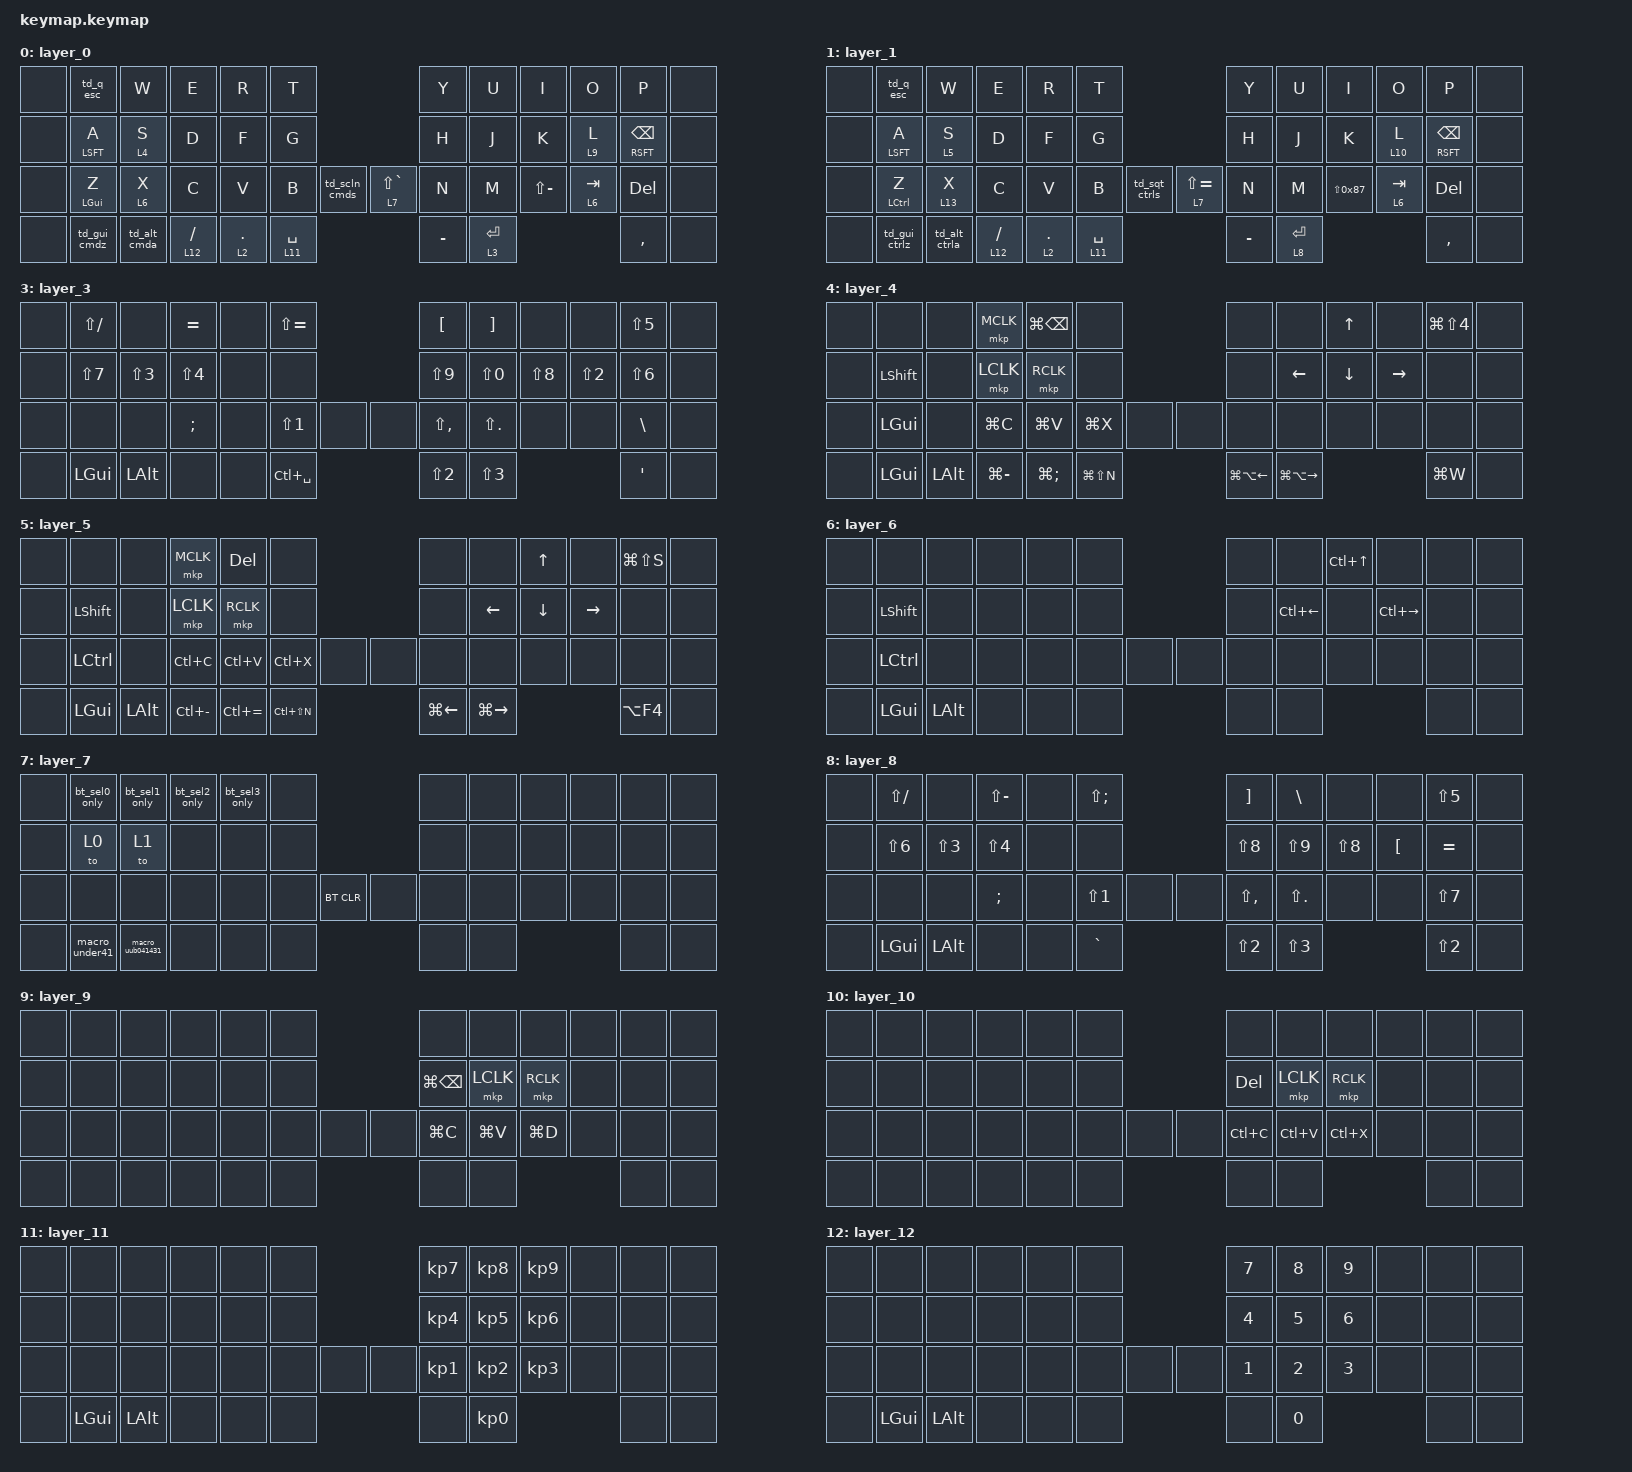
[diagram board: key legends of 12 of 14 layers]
sd#include <dt-bindings/zmk/mouse.h>
#include <behaviors.dtsi>
#include <dt-bindings/zmk/keys.h>
#include <dt-bindings/zmk/bt.h>

/ {


    behaviors {
          macro_under41: macro_under41 {
              compatible = "zmk,behavior-macro";
              #binding-cells = <0>;
              bindings =
              <&kp U>,
              <&kp N>,
              <&kp D>,
              <&kp E>,
        	  <&kp R>,
              <&kp N4>,
              <&kp N1>;
           };
        macro_uub041431: macro_uub041431 {
            compatible = "zmk,behavior-macro";
            #binding-cells = <0>;
            bindings =
            <&kp U>,
            <&kp U>,
            <&kp B>,
            <&kp N0>,
            <&kp N4>,
            <&kp N1>,
            <&kp N4>,
            <&kp N3>,
            <&kp N1>;
          };

         
        bt_sel0_only: bt_sel0_only {
            compatible = "zmk,behavior-macro";
            #binding-cells = <0>;
            bindings =
                <&bt BT_SEL 0>,
                <&bt BT_DISC 1>,
                <&bt BT_DISC 2>,
                <&bt BT_DISC 3>;
        };
       bt_sel1_only: bt_sel1_only {
            compatible = "zmk,behavior-macro";
            #binding-cells = <0>;
            bindings =
                <&bt BT_SEL 1>,
                <&bt BT_DISC 0>,
                <&bt BT_DISC 2>,
                <&bt BT_DISC 3>;
        };
       bt_sel2_only: bt_sel2_only {
            compatible = "zmk,behavior-macro";
            #binding-cells = <0>;
            bindings =
                <&bt BT_SEL 2>,
                <&bt BT_DISC 0>,
                <&bt BT_DISC 1>,
                <&bt BT_DISC 3>;
        };
        bt_sel3_only: bt_sel3_only {
            compatible = "zmk,behavior-macro";
            #binding-cells = <0>;
            bindings =
                <&bt BT_SEL 3>,
                <&bt BT_DISC 1>,
                <&bt BT_DISC 2>,
                <&bt BT_DISC 0>;
        };



   
         mt_cmd_z: mt_cmd_z {                 //Z to komanndo no taiminngutyousei
             compatible = "zmk,behavior-hold-tap";
             #binding-cells = <2>;
             flavor = "tap-preferred";
             tapping-term-ms = <320>;
             bindings = <&kp>, <&kp>;
          };

         mt_ctrl_z: mt_ctrl_z {              //Z to konntoro-ru no taiminngutyousei
             compatible = "zmk,behavior-hold-tap";
             #binding-cells = <2>;
             flavor = "tap-preferred";
             tapping-term-ms = <320>;
             bindings = <&kp>, <&kp>;
          };


    
          mt_lsft_a: mt_lsft_a {              //A to sihuto no taiminngutyousei
               compatible = "zmk,behavior-hold-tap";
               #binding-cells = <2>;
               flavor = "tap-preferred";
               tapping-term-ms = <320>;
               bindings = <&kp>, <&kp>;
           };

         mt_rsft_bspc: mt_rsft_bspc {            //bakkusupe-su to migi sihuto no taiminngutyousei
              compatible = "zmk,behavior-hold-tap";
              #binding-cells = <2>;
              flavor = "tap-preferred";
              tapping-term-ms = <320>;
              bindings = <&kp>, <&kp>;
         };
        td_q_esc: td_q_esc {
            compatible = "zmk,behavior-tap-dance";
            #binding-cells = <0>;
            tapping-term-ms = <200>;
            bindings = < &kp Q &kp ESC >;
        };


        td_gui_cmdz: td_gui_cmdz {   //
            compatible = "zmk,behavior-tap-dance";
            #binding-cells = <0>;
            tapping-term-ms = <200>;
            bindings = < &kp LGUI &kp LG(Z) >;
        };
        td_gui_ctrlz: td_gui_ctrlz {    //
            compatible = "zmk,behavior-tap-dance";
            #binding-cells = <0>;
            tapping-term-ms = <200>;
            bindings = < &kp LGUI &kp LC(Z) >;
        };
        td_alt_cmda: td_alt_cmda {    //
            compatible = "zmk,behavior-tap-dance";
            #binding-cells = <0>;
            tapping-term-ms = <200>;
            bindings = < &kp LALT &kp LG(A) >;
       };
       td_scln_cmds: td_scln_cmds {     //
           compatible = "zmk,behavior-tap-dance";
           #binding-cells = <0>;
           tapping-term-ms = <200>;
           bindings = < &kp LS(SCLN) &kp LG(S) >;
       };
       td_alt_ctrla: td_alt_ctrla {     //
          compatible = "zmk,behavior-tap-dance";
          #binding-cells = <0>;
          tapping-term-ms = <200>;
          bindings = < &kp LALT &kp LC(A) >;
       };
       td_sqt_ctrls: td_sqt_ctrls {
          compatible = "zmk,behavior-tap-dance";
          #binding-cells = <0>;
          tapping-term-ms = <200>;
          bindings = < &kp SQT &kp LC(S) >;
       };

    };


    keymap {
        compatible = "zmk,keymap";

        layer_0 {      //mac home
            bindings =<
                &none &td_q_esc          &kp W          &kp E        &kp R     &kp T                                    &kp Y     &kp U       &kp I          &kp O      &kp P                   &none
				&none &mt_lsft_a LSFT A  &lt 4 S        &kp D        &kp F     &kp G                                    &kp H     &kp J       &kp K          &lt 9 L    &mt_rsft_bspc RSFT BSPC &none
				&none &mt_cmd_z LGUI Z   &lt 6 X        &kp C        &kp V     &kp B     &td_scln_cmds  &lt 7 LS(GRAVE) &kp N     &kp M       &kp LS(MINUS)  &lt 6 TAB  &kp DEL                 &none
				&none &td_gui_cmdz       &td_alt_cmda   &lt 12 SLASH &lt 2 DOT &lt 11 SPACE                             &kp MINUS &lt 3 ENTER                           &kp COMMA               &none
            >;
        };

        layer_1 {     //win home
            bindings =<
                &none &td_q_esc          &kp W           &kp E        &kp R     &kp T                                     &kp Y     &kp U       &kp I          &kp O      &kp P                   &none
			 	&none &mt_lsft_a LSFT A  &lt 5 S         &kp D        &kp F     &kp G                                     &kp H     &kp J       &kp K          &lt 10 L   &mt_rsft_bspc RSFT BSPC &none
				&none &mt_ctrl_z LCTRL Z &lt 13 X        &kp C        &kp V     &kp B     &td_sqt_ctrls   &lt 7 LS(EQUAL) &kp N     &kp M       &kp LS(0x87)   &lt 6 TAB  &kp DEL                 &none
				&none &td_gui_ctrlz      &td_alt_ctrla   &lt 12 SLASH &lt 2 DOT &lt 11 SPACE                              &kp MINUS &lt 8 ENTER                           &kp COMMA               &none
            >;
        };

        layer_2 {    //num common
            bindings =<
                &none &none   &none    &none &none  &none                   &kp F1  &kp F2  &kp F3 &kp F4 &kp F5  &none
				&none &none   &none    &none &none  &none                   &kp F6  &kp F7  &kp F8 &kp F9 &kp F10 &none
				&none &none   &none    &none &none  &none  &none    &none   &kp F11 &kp F12 &none  &none  &none   &none
				&none &none   &none    &none &none  &none                   &none   &none                         &none
            >;
        };


        layer_3{    //simbol mac
            bindings =<
                &none      &kp LS(SLASH) &none      &kp EQUAL  &none &kp LS(EQUAL)                       &kp LBKT      &kp RBKT    &none      &none      &kp LS(N5) &none
				&none      &kp LS(N7)    &kp LS(N3) &kp LS(N4) &none &none                               &kp LS(N9)    &kp LS(N0)  &kp LS(N8) &kp LS(N2) &kp LS(N6) &none
				&none      &none         &none      &kp SCLN   &none &kp LS(N1)     &none          &none &kp LS(COMMA) &kp LS(DOT) &none      &none      &kp BSLH   &none
				&none      &kp LGUI      &kp LALT   &none      &none &kp LC(SPACE)                       &kp LS(N2)    &kp LS(N3)                        &kp SQT    &none
            >;
        };

        layer_4 {   //mouse mac
            bindings =<
                &none      &none      &none     &mkp MCLK     &kp LG(BSPC)  &none                              &none            &none             &kp UP   &none       &kp LG(LS(N4)) &none
				&none      &kp LSHIFT &none     &mkp LCLK     &mkp RCLK     &none                              &none            &kp LEFT          &kp DOWN &kp RIGHT   &none          &none
				&none      &kp LGUI   &none     &kp LG(C)     &kp LG(V)     &kp LG(X)    &none           &none &none            &none             &none    &none       &none          &none
				&none      &kp LGUI   &kp LALT  &kp LG(MINUS) &kp LG(SCLN)  &kp LG(LS(N))                      &kp LG(LA(LEFT)) &kp LG(LA(RIGHT))                      &kp LG(W)      &none
            >;
        };

        layer_5 {   //mouse win
            bindings =<
                &none       &none      &none    &mkp MCLK     &kp DEL       &none                           &none            &none             &kp UP    &none       &kp LG(LS(S)) &none
				&none       &kp LSHIFT &none    &mkp LCLK     &mkp RCLK     &none                           &none            &kp LEFT          &kp DOWN  &kp RIGHT   &none         &none
				&none       &kp LCTRL  &none    &kp LC(C)     &kp LC(V)     &kp LC(X)      &none      &none &none            &none             &none     &none       &none         &none
				&none       &kp LGUI   &kp LALT &kp LC(MINUS) &kp LC(EQUAL) &kp LC(LS(N))                   &kp LG(LEFT)     &kp LG(RIGHT)                           &kp LA(F4)    &none
            >;
        };
        layer_6 {   //scrol   mac
            bindings =<
                &none   &none        &none    &none &none &none                      &none         &none            &kp LC(UP) &none         &none &none
				&none   &kp LSHIFT   &none    &none &none &none                      &none         &kp LC(LEFT)     &none      &kp LC(RIGHT) &none &none
				&none   &kp LCTRL    &none    &none &none &none &none          &none &none         &none            &none      &none         &none &none
				&none   &kp LGUI     &kp LALT &none &none &none                      &none         &none                                     &none &none
            >;
        };
        layer_7 {   //bluetooth etc
            bindings =<
                &none  &bt_sel0_only  &bt_sel1_only    &bt_sel2_only &bt_sel3_only &none                        &none &none &none &none &none &none
				&none  &to 0          &to 1            &none         &none         &none                        &none &none &none &none &none &none
				&none  &none          &none            &none         &none         &none &bt BT_CLR       &none &none &none &none &none &none &none
				&none  &macro_under41 &macro_uub041431 &none         &none         &none                        &none &none             &none &none
            >;
        };
        layer_8 {   ////simbol win
            bindings =<
                &none       &kp LS(SLASH) &none      &kp LS(MINUS) &none &kp LS(SCLN)                        &kp RBKT      &kp BSLH    &none      &none    &kp LS(N5) &none
				&none       &kp LS(N6)    &kp LS(N3) &kp LS(N4)    &none &none                               &kp LS(N8)    &kp LS(N9)  &kp LS(N8) &kp LBKT &kp EQUAL  &none
				&none       &none         &none      &kp SCLN      &none &kp LS(N1)     &none          &none &kp LS(COMMA) &kp LS(DOT) &none      &none    &kp LS(N7) &none
				&none       &kp LGUI      &kp LALT   &none         &none &kp GRAVE                           &kp LS(N2)    &kp LS(N3)                      &kp LS(N2) &none
            >;
        };
       layer_9 {   ////syanthi  mac
            bindings =<
                &none &none &none &none &none &none                    &none        &none     &none     &none &none &none 
				&none &none &none &none &none &none                    &kp LG(BSPC) &mkp LCLK &mkp RCLK &none &none &none 
			    &none &none &none &none &none &none  &none       &none &kp LG(C)    &kp LG(V) &kp LG(D) &none &none &none
			    &none &none &none &none &none &none                    &none        &none                     &none &none 
            >;
        };
       layer_10 {   ////syanthi win
            bindings =<
                &none &none &none &none &none &none                    &none     &none      &none      &none  &none &none 
				&none &none &none &none &none &none                    &kp DEL   &mkp LCLK  &mkp RCLK  &none  &none &none 
			    &none &none &none &none &none &none  &none       &none &kp LC(C) &kp LC(V)  &kp LC(X)  &none  &none &none
			    &none &none &none &none &none &none                    &none     &none                        &none &none 
        
            >;
        };
        layer_11 {   ////num  hankaku
            bindings =<
                &none      &none    &none    &none &none &none                    &kp KP_N7 &kp KP_N8 &kp KP_N9 &none &none &none 
				&none      &none    &none    &none &none &none                    &kp KP_N4 &kp KP_N5 &kp KP_N6 &none &none &none 
			    &none      &none    &none    &none &none &none  &none       &none &kp KP_N1 &kp KP_N2 &kp KP_N3 &none &none &none
			    &none      &kp LGUI &kp LALT &none &none &none                    &none     &kp KP_N0                 &none &none 
        
            >;
        };
        layer_12 {   ////num  zennkaku
            bindings =<
                &none      &none    &none    &none &none &none                    &kp N7 &kp N8 &kp N9 &none &none &none 
				&none      &none    &none    &none &none &none                    &kp N4 &kp N5 &kp N6 &none &none &none 
			    &none      &none    &none    &none &none &none  &none       &none &kp N1 &kp N2 &kp N3 &none &none &none
			    &none      &kp LGUI &kp LALT &none &none &none                    &none  &kp N0              &none &none 
        
            >;
        };
        layer_13 {   //scrol  win
            bindings =<
                &none   &none        &none    &none &none &none                      &none         &none            &kp LG(TAB) &none             &none &none
				&none   &kp LSHIFT   &none    &none &none &none                      &none         &kp LG(LC(LEFT)) &none       &kp LC(LG(RIGHT)) &none &none
				&none   &kp LCTRL    &none    &none &none &none &none          &none &none         &none            &none       &none             &none &none
				&none   &kp LGUI     &kp LALT &none &none &none                      &none         &none                                          &none &none
            >;
        };

    };
};
